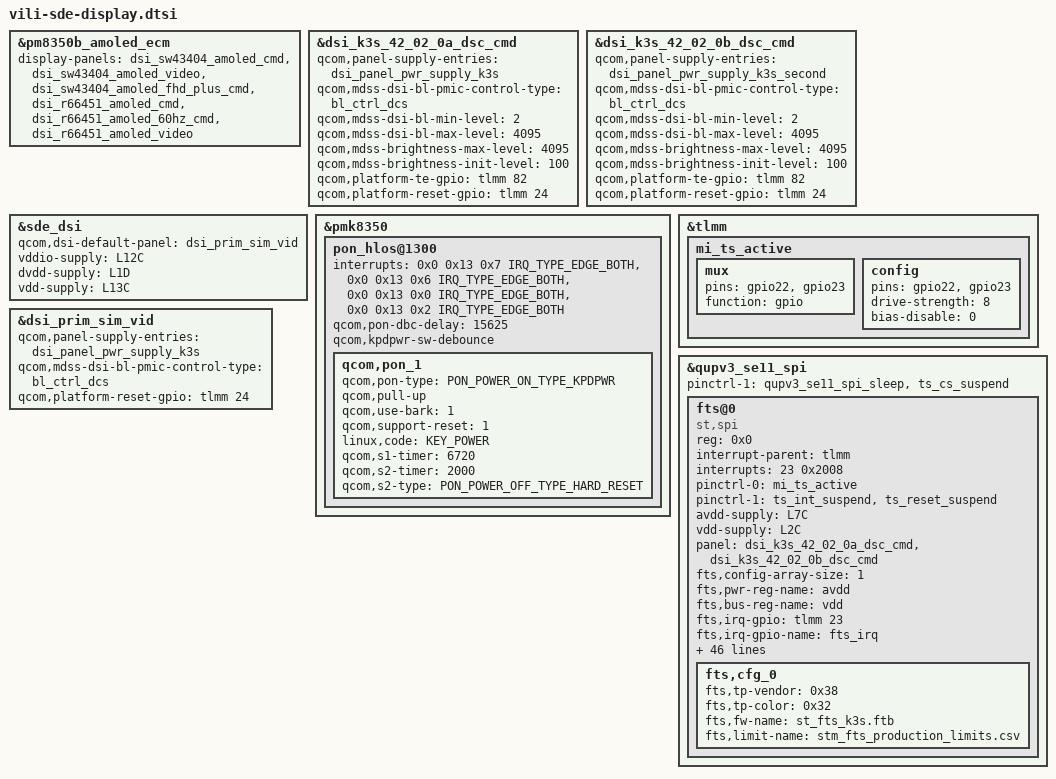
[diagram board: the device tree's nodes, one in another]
#include "lahaina-sde-display.dtsi"

&pm8350b_amoled_ecm {
	display-panels = <&dsi_sw43404_amoled_cmd
			&dsi_sw43404_amoled_video
			&dsi_sw43404_amoled_fhd_plus_cmd
			&dsi_r66451_amoled_cmd
			&dsi_r66451_amoled_60hz_cmd
			&dsi_r66451_amoled_video>;
};

&dsi_k3s_42_02_0a_dsc_cmd {
	qcom,panel-supply-entries = <&dsi_panel_pwr_supply_k3s>;
	qcom,mdss-dsi-bl-pmic-control-type = "bl_ctrl_dcs";
	qcom,mdss-dsi-bl-min-level = <2>;
	qcom,mdss-dsi-bl-max-level = <4095>;
	qcom,mdss-brightness-max-level = <4095>;
	qcom,mdss-brightness-init-level = <100>;
	qcom,platform-te-gpio = <&tlmm 82 0>;
	qcom,platform-reset-gpio = <&tlmm 24 0>;
};

&dsi_k3s_42_02_0b_dsc_cmd {
	qcom,panel-supply-entries = <&dsi_panel_pwr_supply_k3s_second>;
	qcom,mdss-dsi-bl-pmic-control-type = "bl_ctrl_dcs";
	qcom,mdss-dsi-bl-min-level = <2>;
	qcom,mdss-dsi-bl-max-level = <4095>;
	qcom,mdss-brightness-max-level = <4095>;
	qcom,mdss-brightness-init-level = <100>;
	qcom,platform-te-gpio = <&tlmm 82 0>;
	qcom,platform-reset-gpio = <&tlmm 24 0>;
};

&sde_dsi {
	qcom,dsi-default-panel = <&dsi_sim_vid>;
};

&pmk8350 {
	pon_hlos@1300 {
		interrupts = <0x0 0x13 0x7 IRQ_TYPE_EDGE_BOTH>,
			     <0x0 0x13 0x6 IRQ_TYPE_EDGE_BOTH>,
			     <0x0 0x13 0x0 IRQ_TYPE_EDGE_BOTH>,
			     <0x0 0x13 0x2 IRQ_TYPE_EDGE_BOTH>;
		interrupt-names = "kpdpwr", "resin", "kpdpwr-bark",
				"kpdpwr-resin-bark";
		qcom,pon-dbc-delay = <15625>;
		qcom,kpdpwr-sw-debounce;
		qcom,pon_1 {
			qcom,pon-type = <PON_POWER_ON_TYPE_KPDPWR>;
			qcom,pull-up;
			qcom,use-bark = <1>;
			qcom,support-reset = <1>;
			linux,code = <KEY_POWER>;
			qcom,s1-timer = <6720>;
			qcom,s2-timer = <2000>;
			qcom,s2-type = <PON_POWER_OFF_TYPE_HARD_RESET>;
		};
	};
};

&tlmm {
	mi_ts_active: mi_ts_active {
		mux {
			pins = "gpio22", "gpio23";
			function = "gpio";
		};

		config {
			pins = "gpio22", "gpio23";
			drive-strength = <8>;
			bias-disable = <0>;
		};
	};
};

&dsi_prim_sim_vid {
	qcom,panel-supply-entries = <&dsi_panel_pwr_supply_k3s>;
	qcom,mdss-dsi-bl-pmic-control-type = "bl_ctrl_dcs";
	qcom,platform-reset-gpio = <&tlmm 24 0>;
};

&sde_dsi {
	qcom,dsi-default-panel = <&dsi_prim_sim_vid>;
	vddio-supply = <&L12C>;
	dvdd-supply = <&L1D>;
	vdd-supply = <&L13C>;
};

&qupv3_se11_spi {
	status = "ok";
	pinctrl-1 = <&qupv3_se11_spi_sleep &ts_cs_suspend>;
	fts@0 {
		status = "ok";
		compatible = "st,spi";
		reg = <0x0>;
		interrupt-parent = <&tlmm>;
		interrupts = <23 0x2008>;
		pinctrl-names = "pmx_ts_active", "pmx_ts_suspend";
		pinctrl-0 = <&mi_ts_active>;
		pinctrl-1 = <&ts_int_suspend &ts_reset_suspend>;
		avdd-supply = <&L7C>;
		vdd-supply = <&L2C>;
		panel = <&dsi_k3s_42_02_0a_dsc_cmd &dsi_k3s_42_02_0b_dsc_cmd>;
		fts,config-array-size = <1>;
		fts,pwr-reg-name = "avdd";
		fts,bus-reg-name = "vdd";
		fts,irq-gpio = <&tlmm 23 0x2008>;
		fts,irq-gpio-name = "fts_irq";
		fts,reset-gpio-enable;
		fts,reset-gpio = <&tlmm 22 0x00>;
		fts,reset-gpio-name = "fts_rst";
		fts,irq-flags = <0x2008>;
		fts,x-max = <10800>;
		fts,y-max = <24000>;
		spi-max-frequency = <7000000>;
		fts,default-fw-name = "st_fts_k3s.ftb";
		/*
		fts,touch-up-threshold-min = <40>;
		fts,touch-up-threshold-max = <120>;
		fts,touch-up-threshold-def = <80>;
		fts,touch-tolerance-min = <5>;
		fts,touch-tolerance-max = <35>;
		fts,touch-tolerance-def = <25>;
		*/
		fts,non-curved-display = <1>;
		fts,support-super-resolution = <1>;
		fts,touch-follow-performance-def = <3>;
		fts,touch-tap-sensitivity-def = <4>;
		fts,touch-aim-sensitivity-def = <3>;
		fts,touch-tap-stability-def = <3>;
		fts,cornerfilter-area-step1 = <100>;
		fts,cornerfilter-area-step2 = <170>;
		fts,cornerfilter-area-step3 = <250>;
		fts,touch-deadzone-filter-ver = <2 0 0 0 0 0 0 0
										2 1 0 0 0 0 0 0
										2 2 0 0 0 0 0 0
										2 3 0 0 0 0 0 0>;
		fts,touch-deadzone-filter-hor = <2 0 0 0 0 0 0 0
										2 1 0 0 0 0 0 0
										2 2 0 0 0 0 0 0
										2 3 0 0 0 0 0 0>;
		fts,touch-edgezone-filter-ver = <1 0 0 0 0 0 0 0
										1 1 0 0 0 0 0 0
										1 2 0 0 40 2399 0 0
										1 3 1039 0 1079 2399 0 0>;
		fts,touch-edgezone-filter-hor = <1 0 0 0 1079 40 0 0
										1 1 0 2359 1079 2399 0 0
										1 2 0 0 40 2399 0 0
										1 3 1039 0 1079 2399 0 0>;
		fts,touch-cornerzone-filter-ver = <0 0 0 0 0 0 0 0
										0 1 0 0 0 0 0 0
										0 2 0 2099 150 2399 0 0
										0 3 929 2099 1079 2399 0 0>;
		fts,touch-cornerzone-filter-hor1 = <0 0 0 0 150 150 0 0
										0 1 0 0 0 0 0 0
										0 2 0 2249 150 2399 0 0
										0 3 0 0 0 0 0 0>;
		fts,touch-cornerzone-filter-hor2 = <0 0 0 0 0 0 0 0
										0 1 929 0 1079 150 0 0
										0 2 0 0 0 0 0 0
										0 3 929 2249 1079 2399 0 0>;
		fts,touch-normal-deadzone-filter-hor = <2 0 0 0 1079 0 0 0
										2 1 0 2399 1079 2399 0 0
										2 2 0 0 0 2399 0 0
										2 3 1079 0 1079 2399 0 0>;
		fts,touch-normal-edgezone-filter-hor = <1 0 0 0 1079 30 0 0
										1 1 0 2369 1079 2399 0 0
										1 2 0 0 30 2399 0 0
										1 3 1049 0 1079 2399 0 0>;
		fts,touch-normal-cornerzone-filter-hor1 = <0 0 0 0 170 170 0 0
										0 1 0 0 0 0 0 0
										0 2 0 2229 170 2399 0 0
										0 3 0 0 0 0 0 0>;
		fts,touch-normal-cornerzone-filter-hor2 = <0 0 0 0 0 0 0 0
										0 1 909 0 1079 170 0 0
										0 2 0 0 0 0 0 0
										0 3 909 2229 1079 2399 0 0>;
		fts,touch-follow-performance = <10 15 1
										8 15 1
										6 15 1
										4 15 1
										2 15 1>;
		fts,touch-tap-sensitivity = <160 150 140 120 100>;
		fts,touch-aim-sensitivity = <10 8 6 4 2>;
		fts,touch-tap-stability = <8 12 15 18 25>;
		fts,touch-expert-array = <6 15 1 120 6 15
								  2 15 1 120 4 15
								  4 15 1 120 2 15>;
		fts,cfg_0 {
			fts,tp-vendor = <0x38>;
			fts,tp-color = <0x32>;
			fts,fw-name = "st_fts_k3s.ftb";
			fts,limit-name = "stm_fts_production_limits.csv";
		};
	};
};
